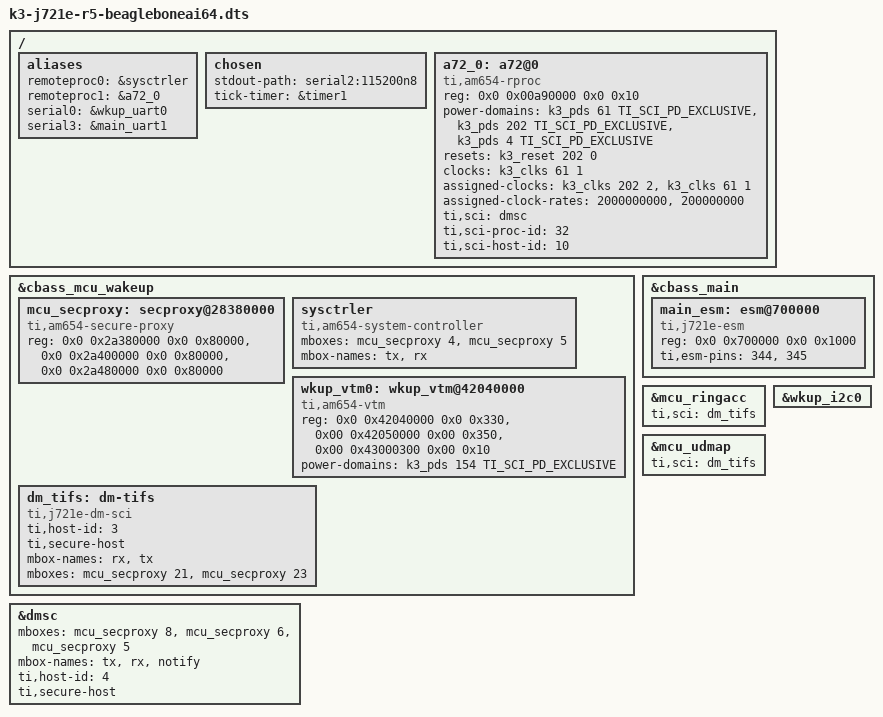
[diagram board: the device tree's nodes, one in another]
// SPDX-License-Identifier: GPL-2.0
/*
 * https://beagleboard.org/ai-64
 *
 * Copyright (C) 2022-2023 Texas Instruments Incorporated - https://www.ti.com/
 * Copyright (C) 2022 Jason Kridner, BeagleBoard.org Foundation
 * Copyright (C) 2022-2023 Robert Nelson, BeagleBoard.org Foundation
 */

#include "k3-j721e-beagleboneai64.dts"
#include "k3-j721e-ddr-beagleboneai64-lp4-3200.dtsi"
#include "k3-j721e-ddr.dtsi"

#include "k3-j721e-beagleboneai64-u-boot.dtsi"

/ {
	aliases {
		remoteproc0 = &sysctrler;
		remoteproc1 = &a72_0;
		serial0 = &wkup_uart0;
		serial3 = &main_uart1;
	};

	chosen {
		stdout-path = "serial2:115200n8";
		tick-timer = &timer1;
	};

	a72_0: a72@0 {
		compatible = "ti,am654-rproc";
		reg = <0x0 0x00a90000 0x0 0x10>;
		power-domains = <&k3_pds 61 TI_SCI_PD_EXCLUSIVE>,
				<&k3_pds 202 TI_SCI_PD_EXCLUSIVE>,
				<&k3_pds 4 TI_SCI_PD_EXCLUSIVE>;
		resets = <&k3_reset 202 0>;
		clocks = <&k3_clks 61 1>;
		assigned-clocks = <&k3_clks 202 2>, <&k3_clks 61 1>;
		assigned-clock-rates = <2000000000>, <200000000>;
		ti,sci = <&dmsc>;
		ti,sci-proc-id = <32>;
		ti,sci-host-id = <10>;
		bootph-pre-ram;
	};

};

&cbass_mcu_wakeup {
	mcu_secproxy: secproxy@28380000 {
		bootph-pre-ram;
		compatible = "ti,am654-secure-proxy";
		reg = <0x0 0x2a380000 0x0 0x80000>,
		      <0x0 0x2a400000 0x0 0x80000>,
		      <0x0 0x2a480000 0x0 0x80000>;
		reg-names = "rt", "scfg", "target_data";
		#mbox-cells = <1>;
	};

	sysctrler: sysctrler {
		bootph-pre-ram;
		compatible = "ti,am654-system-controller";
		mboxes= <&mcu_secproxy 4>, <&mcu_secproxy 5>;
		mbox-names = "tx", "rx";
	};

	wkup_vtm0: wkup_vtm@42040000 {
		compatible = "ti,am654-vtm", "ti,j721e-avs", "ti,j721e-vtm";
		reg = <0x0 0x42040000 0x0 0x330>,
		      <0x00 0x42050000 0x00 0x350>,
		      <0x00 0x43000300 0x00 0x10>;
		power-domains = <&k3_pds 154 TI_SCI_PD_EXCLUSIVE>;
		#thermal-sensor-cells = <1>;
	};

	dm_tifs: dm-tifs {
		compatible = "ti,j721e-dm-sci";
		ti,host-id = <3>;
		ti,secure-host;
		mbox-names = "rx", "tx";
		mboxes= <&mcu_secproxy 21>,
				<&mcu_secproxy 23>;
		bootph-pre-ram;
	};
};

&cbass_main {
	main_esm: esm@700000 {
		compatible = "ti,j721e-esm";
		reg = <0x0 0x700000 0x0 0x1000>;
		ti,esm-pins = <344>, <345>;
		bootph-pre-ram;
	};
};

&dmsc {
	mboxes= <&mcu_secproxy 8>, <&mcu_secproxy 6>, <&mcu_secproxy 5>;
	mbox-names = "tx", "rx", "notify";
	ti,host-id = <4>;
	ti,secure-host;
};

&mcu_ringacc {
	ti,sci = <&dm_tifs>;
};

&mcu_udmap {
	ti,sci = <&dm_tifs>;
};

/* EEPROM might be read before SYSFW is available */
&wkup_i2c0 {
	/delete-property/ power-domains;
};
